VERSION ""

NS_ :

BS_:

BU_: Host KincoDrive

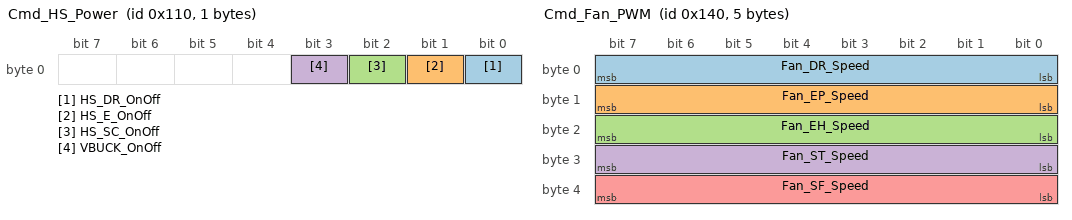
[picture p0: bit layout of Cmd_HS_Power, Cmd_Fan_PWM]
BO_ 272 Cmd_HS_Power: 1 Host
 SG_ HS_DR_OnOff : 0|1@1+ (1,0) [0|1] "" KincoDrive
 SG_ HS_E_OnOff : 1|1@1+ (1,0) [0|1] "" KincoDrive
 SG_ HS_SC_OnOff : 2|1@1+ (1,0) [0|1] "" KincoDrive
 SG_ VBUCK_OnOff : 3|1@1+ (1,0) [0|1] "" KincoDrive

BO_ 320 Cmd_Fan_PWM: 5 Host
 SG_ Fan_DR_Speed : 0|8@1+ (1,0) [0|100] "%" KincoDrive
 SG_ Fan_EP_Speed : 8|8@1+ (1,0) [0|100] "%" KincoDrive
 SG_ Fan_EH_Speed : 16|8@1+ (1,0) [0|100] "%" KincoDrive
 SG_ Fan_ST_Speed : 24|8@1+ (1,0) [0|100] "%" KincoDrive
 SG_ Fan_SF_Speed : 32|8@1+ (1,0) [0|100] "%" KincoDrive

BO_ 512 Cmd_EEPROM: 1 Host
 SG_ EEPROM_Action : 0|8@1+ (1,0) [0|1] "" KincoDrive

BO_ 1536 Bcast_Voltages: 4 KincoDrive
 SG_ Bus24V_Voltage : 0|16@1+ (1,0) [0|65535] "mV" Host
 SG_ Bus12V_Voltage : 16|16@1+ (1,0) [0|65535] "mV" Host

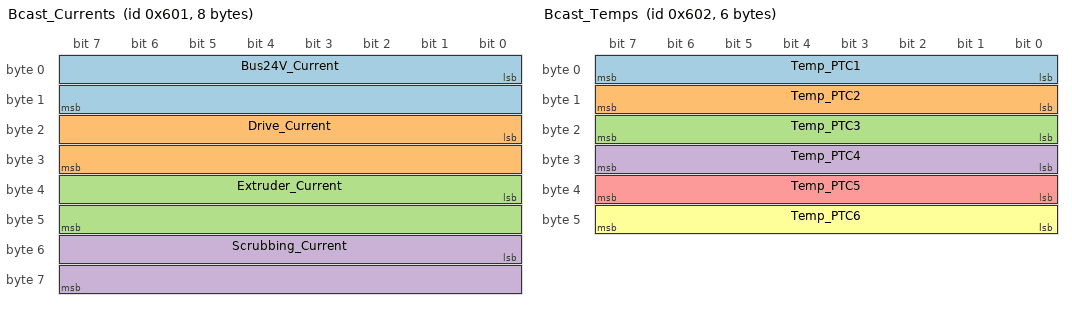
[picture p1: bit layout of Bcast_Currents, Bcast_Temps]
BO_ 1537 Bcast_Currents: 8 KincoDrive
 SG_ Bus24V_Current : 0|16@1+ (1,0) [0|65535] "mA" Host
 SG_ Drive_Current : 16|16@1+ (1,0) [0|65535] "mA" Host
 SG_ Extruder_Current : 32|16@1+ (1,0) [0|65535] "mA" Host
 SG_ Scrubbing_Current : 48|16@1+ (1,0) [0|65535] "mA" Host

BO_ 1538 Bcast_Temps: 6 KincoDrive
 SG_ Temp_PTC1 : 0|8@1+ (1,-40) [-40|215] "degC" Host
 SG_ Temp_PTC2 : 8|8@1+ (1,-40) [-40|215] "degC" Host
 SG_ Temp_PTC3 : 16|8@1+ (1,-40) [-40|215] "degC" Host
 SG_ Temp_PTC4 : 24|8@1+ (1,-40) [-40|215] "degC" Host
 SG_ Temp_PTC5 : 32|8@1+ (1,-40) [-40|215] "degC" Host
 SG_ Temp_PTC6 : 40|8@1+ (1,-40) [-40|215] "degC" Host

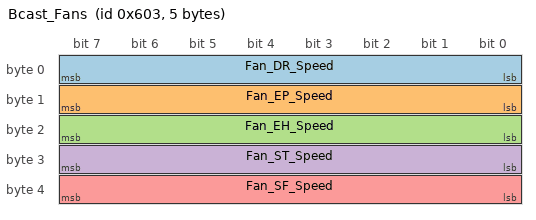
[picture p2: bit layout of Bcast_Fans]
BO_ 1539 Bcast_Fans: 5 KincoDrive
 SG_ Fan_DR_Speed : 0|8@1+ (1,0) [0|100] "%" Host
 SG_ Fan_EP_Speed : 8|8@1+ (1,0) [0|100] "%" Host
 SG_ Fan_EH_Speed : 16|8@1+ (1,0) [0|100] "%" Host
 SG_ Fan_ST_Speed : 24|8@1+ (1,0) [0|100] "%" Host
 SG_ Fan_SF_Speed : 32|8@1+ (1,0) [0|100] "%" Host

BO_ 1540 Bcast_GPIO: 8 KincoDrive
 SG_ HS_DR_Enable : 0|1@1+ (1,0) [0|1] "" Host
 SG_ HS_E_Enable : 1|1@1+ (1,0) [0|1] "" Host
 SG_ HS_SC_Enable : 2|1@1+ (1,0) [0|1] "" Host
 SG_ VBUCK_Enable : 3|1@1+ (1,0) [0|1] "" Host
 SG_ HS_DR_PwrGood : 8|1@1+ (1,0) [0|1] "" Host
 SG_ HS_E_PwrGood : 9|1@1+ (1,0) [0|1] "" Host
 SG_ HS_SC_PwrGood : 10|1@1+ (1,0) [0|1] "" Host
 SG_ HS_DR_Fault : 16|1@1+ (1,0) [0|1] "" Host
 SG_ HS_E_Fault : 17|1@1+ (1,0) [0|1] "" Host
 SG_ HS_SC_Fault : 18|1@1+ (1,0) [0|1] "" Host
 SG_ ESTOP_NO_Pin : 24|1@1+ (1,0) [0|1] "" Host
 SG_ ESTOP_NC_Pin : 25|1@1+ (1,0) [0|1] "" Host
 SG_ ESTOP_Triggered : 26|1@1+ (1,0) [0|1] "" Host
 SG_ ESTOP_WiringFault : 27|1@1+ (1,0) [0|1] "" Host
 SG_ LED_Out : 28|1@1+ (1,0) [0|1] "" Host
 SG_ BlueButton : 29|1@1+ (1,0) [0|1] "" Host
 SG_ EH_Top_NO : 32|1@1+ (1,0) [0|1] "" Host
 SG_ EH_Bot_NO : 33|1@1+ (1,0) [0|1] "" Host
 SG_ EP_Top_NO : 34|1@1+ (1,0) [0|1] "" Host
 SG_ EP_Bot_NO : 35|1@1+ (1,0) [0|1] "" Host
 SG_ SC_Top_NO : 36|1@1+ (1,0) [0|1] "" Host
 SG_ EH_Top_NC : 40|1@1+ (1,0) [0|1] "" Host
 SG_ EP_Top_NC : 42|1@1+ (1,0) [0|1] "" Host
 SG_ EP_Bot_NC : 43|1@1+ (1,0) [0|1] "" Host
 SG_ SC_Top_NC : 44|1@1+ (1,0) [0|1] "" Host
 SG_ Dbg_Cmd_Count : 48|8@1+ (1,0) [0|255] "" Host
 SG_ Dbg_ISR_Count : 56|8@1+ (1,0) [0|255] "" Host

CM_ BU_ KincoDrive "KincoDrive Control Module V5.4 - 11-bit standard CAN IDs";
CM_ BU_ Host "Host controller / CAN analyzer";

CM_ BO_ 272 "CMD 0x110: High-side power control. DLC=1. bit0=DR bit1=E bit2=SC bit3=VBUCK. 0=OFF 1=ON.";
CM_ BO_ 320 "CMD 0x140: Fan PWM speed. DLC=5. One byte per fan (0-100%). Bytes 0-4 = DR/EP/EH/ST/SF.";
CM_ BO_ 512 "CMD 0x200: EEPROM config. DLC=1. Byte0: 0=Load hard-coded defaults and apply, 1=Save current live state to EEPROM.";

CM_ BO_ 1536 "BCAST 0x600: 24V and 12V bus voltages in mV (u16 LE). Period: 500 ms.";
CM_ BO_ 1537 "BCAST 0x601: 24V bus and per-module high-side currents in mA (u16 LE). Period: 500 ms.";
CM_ BO_ 1538 "BCAST 0x602: 6 PTC thermistor temperatures. Wire: value = degC + 40. Period: 500 ms.";
CM_ BO_ 1539 "BCAST 0x603: Fan tachometer speed as % of max RPM. Period: 500 ms.";
CM_ BO_ 1540 "BCAST 0x604: GPIO pin states and debug counters. Period: 500 ms.";

CM_ SG_ 1540 HS_DR_PwrGood "Active LOW inverted: 1=power good, 0=not good";
CM_ SG_ 1540 HS_E_PwrGood "Active LOW inverted: 1=power good, 0=not good";
CM_ SG_ 1540 HS_SC_PwrGood "Active LOW inverted: 1=power good, 0=not good";
CM_ SG_ 1540 HS_DR_Fault "Active LOW inverted: 1=fault active, 0=normal";
CM_ SG_ 1540 HS_E_Fault "Active LOW inverted: 1=fault active, 0=normal";
CM_ SG_ 1540 HS_SC_Fault "Active LOW inverted: 1=fault active, 0=normal";
CM_ SG_ 1540 ESTOP_NO_Pin "Raw NO input pin: 1=HIGH";
CM_ SG_ 1540 ESTOP_NC_Pin "Raw NC input pin: 1=HIGH";
CM_ SG_ 1540 ESTOP_Triggered "Debounced ESTOP state: 1=triggered";
CM_ SG_ 1540 ESTOP_WiringFault "1=NO/NC state inconsistent (wiring fault)";
CM_ SG_ 1540 EH_Top_NO "Extruder Head top endstop, NO contact: 1=HIGH";
CM_ SG_ 1540 EH_Bot_NO "Extruder Head bottom endstop, NO contact: 1=HIGH (NO-only switch)";
CM_ SG_ 1540 EP_Top_NO "Extruder Platform top endstop, NO contact: 1=HIGH";
CM_ SG_ 1540 EP_Bot_NO "Extruder Platform bottom endstop, NO contact: 1=HIGH";
CM_ SG_ 1540 SC_Top_NO "Scrubbing top endstop, NO contact: 1=HIGH";
CM_ SG_ 1540 EH_Top_NC "Extruder Head top endstop, NC contact: 1=HIGH";
CM_ SG_ 1540 EP_Top_NC "Extruder Platform top endstop, NC contact: 1=HIGH";
CM_ SG_ 1540 EP_Bot_NC "Extruder Platform bottom endstop, NC contact: 1=HIGH";
CM_ SG_ 1540 SC_Top_NC "Scrubbing top endstop, NC contact: 1=HIGH";
CM_ SG_ 1540 Dbg_Cmd_Count "DEBUG: wrapping counter +1 each CAN frame dequeued by AppLogic";
CM_ SG_ 1540 Dbg_ISR_Count "DEBUG: wrapping counter +1 each CAN frame received by ISR";

BA_DEF_  "BusType" STRING ;
BA_DEF_ BO_  "GenMsgCycleTime" INT 0 10000;
BA_DEF_DEF_  "BusType" "CAN";
BA_DEF_DEF_  "GenMsgCycleTime" 0;

BA_ "GenMsgCycleTime" BO_ 1536 500;
BA_ "GenMsgCycleTime" BO_ 1537 500;
BA_ "GenMsgCycleTime" BO_ 1538 500;
BA_ "GenMsgCycleTime" BO_ 1539 500;
BA_ "GenMsgCycleTime" BO_ 1540 500;
